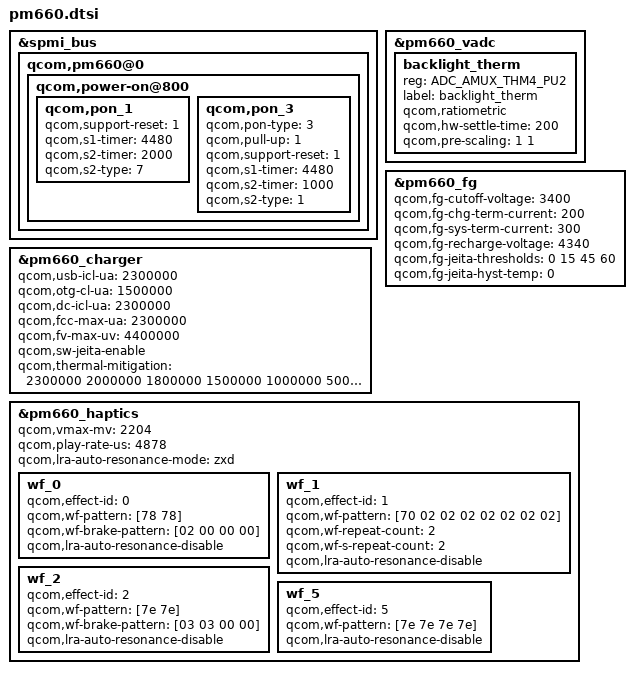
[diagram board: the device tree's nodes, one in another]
&spmi_bus {
	qcom,pm660@0 {
		qcom,power-on@800 {
			qcom,pon_1 {
				qcom,support-reset = <1>;
				qcom,s1-timer = <4480>;
				qcom,s2-timer = <2000>;
				qcom,s2-type = <7>;
			};

			qcom,pon_3 {
				qcom,pon-type = <3>;
				qcom,pull-up = <1>;
				qcom,support-reset = <1>;
				qcom,s1-timer = <4480>;
				qcom,s2-timer = <1000>;
				qcom,s2-type = <1>;
			};
		};
	};
};

&pm660_vadc {
	backlight_therm {
		reg = <ADC_AMUX_THM4_PU2>;
		label = "backlight_therm";
		qcom,ratiometric;
		qcom,hw-settle-time = <200>;
		qcom,pre-scaling = <1 1>;
	};
};

&pm660_charger {
	qcom,usb-icl-ua = <2300000>;
	qcom,otg-cl-ua = <1500000>;
	qcom,dc-icl-ua = <2300000>;
	qcom,fcc-max-ua = <2300000>;
	qcom,fv-max-uv  = <4400000>;
	qcom,sw-jeita-enable;
	qcom,thermal-mitigation = <2300000 2000000 1800000 1500000
			1000000 500000 100000>;
};

&pm660_fg {
	qcom,fg-cutoff-voltage = <3400>;
	qcom,fg-chg-term-current = <200>;
	qcom,fg-sys-term-current = <300>;
	qcom,fg-recharge-voltage = <4340>;
	qcom,fg-jeita-thresholds = <0 15 45 60>;
	qcom,fg-jeita-hyst-temp = <0>;
};

&pm660_haptics {
	qcom,vmax-mv = <2204>;
	qcom,play-rate-us = <4878>;
	qcom,lra-auto-resonance-mode = "zxd";

	/delete-node/ wf_0;
	/delete-node/ wf_1;
	/delete-node/ wf_2;
	/delete-node/ wf_3;
	/delete-node/ wf_4;
	/delete-node/ wf_5;

	wf_0 {
		/* CLICK */
		qcom,effect-id = <0>;
		qcom,wf-pattern = [78 78];
		qcom,wf-brake-pattern = [02 00 00 00];
		qcom,lra-auto-resonance-disable;
	};
	wf_1 {
		/* DOUBLE CLICK */
		qcom,effect-id = <1>;
		qcom,wf-pattern = [70 02 02 02 02 02 02 02];
		qcom,wf-repeat-count = <2>;
		qcom,wf-s-repeat-count = <2>;
		qcom,lra-auto-resonance-disable;
	};
	wf_2 {
		/* TICK */
		qcom,effect-id = <2>;
		qcom,wf-pattern = [7e 7e];
		qcom,wf-brake-pattern = [03 03 00 00];
		qcom,lra-auto-resonance-disable;
	};
	wf_5 {
		/* HEAVY CLICK */
		qcom,effect-id = <5>;
		qcom,wf-pattern = [7e 7e 7e 7e];
		qcom,lra-auto-resonance-disable;
	};
};
